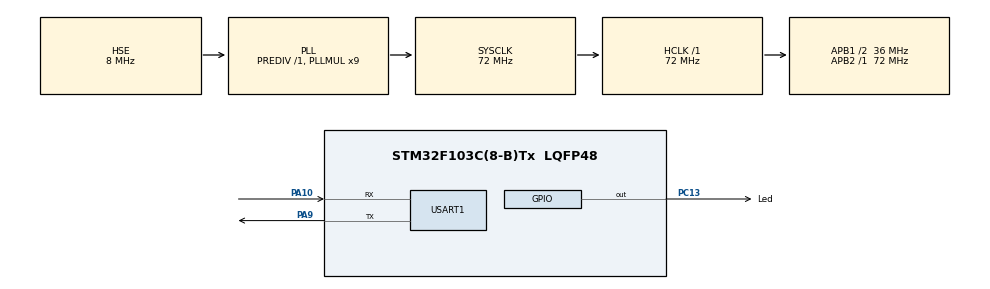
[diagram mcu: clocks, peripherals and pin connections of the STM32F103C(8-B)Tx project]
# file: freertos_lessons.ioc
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FREERTOS.INCLUDE_vTaskDelayUntil=1
FREERTOS.Tasks01=defaultTask,0,128,StartDefaultTask,Default,NULL,Dynamic,NULL,NULL
FREERTOS.configTICK_RATE_HZ=100
FREERTOS.configUSE_IDLE_HOOK=1
FREERTOS.configUSE_PREEMPTION=0
Mcu.Family=STM32F1
Mcu.Name=STM32F103C(8-B)Tx
Mcu.Package=LQFP48
NVIC.PriorityGroup=NVIC_PRIORITYGROUP_4
NVIC.TIM1_UP_IRQn=true\:0\:0\:false\:false\:true\:false\:false\:true
NVIC.TimeBase=TIM1_UP_IRQn
NVIC.TimeBaseIP=TIM1
PA10.Mode=Asynchronous
PA10.Signal=USART1_RX
PA13.Mode=Serial_Wire
PA13.Signal=SYS_JTMS-SWDIO
PA14.Mode=Serial_Wire
PA14.Signal=SYS_JTCK-SWCLK
PA9.Mode=Asynchronous
PA9.Signal=USART1_TX
PC13-TAMPER-RTC.GPIO_Label=Led
PC13-TAMPER-RTC.Signal=GPIO_Output
PD0-OSC_IN.Mode=HSE-External-Oscillator
PD0-OSC_IN.Signal=RCC_OSC_IN
PD1-OSC_OUT.Mode=HSE-External-Oscillator
PD1-OSC_OUT.Signal=RCC_OSC_OUT
ProjectManager.HeapSize=0x200
ProjectManager.StackSize=0x400
ProjectManager.TargetToolchain=STM32CubeIDE
RCC.AHBFreq_Value=72000000
RCC.APB1CLKDivider=RCC_HCLK_DIV2
RCC.APB1Freq_Value=36000000
RCC.APB1TimFreq_Value=72000000
RCC.APB2Freq_Value=72000000
RCC.APB2TimFreq_Value=72000000
RCC.HCLKFreq_Value=72000000
RCC.PLLMUL=RCC_PLL_MUL9
RCC.PLLSourceVirtual=RCC_PLLSOURCE_HSE
RCC.SYSCLKFreq_VALUE=72000000
RCC.SYSCLKSource=RCC_SYSCLKSOURCE_PLLCLK
RCC.USBFreq_Value=72000000
USART1.VirtualMode=VM_ASYNC
VP_FREERTOS_VS_CMSIS_V1.Mode=CMSIS_V1
VP_SYS_VS_tim1.Mode=TIM1
board=custom

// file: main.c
/* USER CODE BEGIN Header */
/**
  ******************************************************************************
  * @file           : main.c
  * @brief          : Main program body
  ******************************************************************************
  * @attention
  *
  * <h2><center>&copy; Copyright (c) 2021 STMicroelectronics.
  * All rights reserved.</center></h2>
  *
  * This software component is licensed by ST under BSD 3-Clause license,
  * the "License"; You may not use this file except in compliance with the
  * License. You may obtain a copy of the License at:
  *                        opensource.org/licenses/BSD-3-Clause
  *
  ******************************************************************************
  */
/* USER CODE END Header */
#include "main.h"
#include "cmsis_os.h"

/* USER CODE BEGIN PD */
#define MY_STR "State of led pin is:  \r\n"
/* USER CODE END PD */

UART_HandleTypeDef huart1;

osThreadId defaultTaskHandle;
/* USER CODE BEGIN PV */
uint8_t input_value = 0;
/* USER CODE END PV */

void SystemClock_Config(void);
static void MX_GPIO_Init(void);
static void MX_USART1_UART_Init(void);
void StartDefaultTask(void const * argument);

/* USER CODE BEGIN PFP */
void BlinkingLedUntilTask();
void input_handler_task();
void config_output_task();
void led_status_task();
/* USER CODE END PFP */

int main(void)
{

  /* MCU Configuration--------------------------------------------------------*/

  /* Reset of all peripherals, Initializes the Flash interface and the Systick. */
  HAL_Init();

  /* Configure the system clock */
  SystemClock_Config();

  /* Initialize all configured peripherals */
  MX_GPIO_Init();
  MX_USART1_UART_Init();

  /* USER CODE BEGIN RTOS_QUEUES */
  /* add queues, ... */
  if (0) {
  /* USER CODE END RTOS_QUEUES */

  /* Create the thread(s) */
  /* definition and creation of defaultTask */
  osThreadDef(defaultTask, StartDefaultTask, osPriorityNormal, 0, 128);
  defaultTaskHandle = osThreadCreate(osThread(defaultTask), NULL);

  /* USER CODE BEGIN RTOS_THREADS */
  }
//  xTaskCreate(BlinkingLedUntilTask, NULL, configMINIMAL_STACK_SIZE, NULL, 1, NULL);
  xTaskCreate(input_handler_task, NULL, configMINIMAL_STACK_SIZE, NULL, 1, NULL);
  xTaskCreate(config_output_task, NULL, configMINIMAL_STACK_SIZE, NULL, 2, NULL);
  xTaskCreate(led_status_task, NULL, configMINIMAL_STACK_SIZE, NULL, 3, NULL);
  vTaskStartScheduler();
  /* add threads, ... */
  /* USER CODE END RTOS_THREADS */

  /* Start scheduler */
  osKernelStart();

  /* We should never get here as control is now taken by the scheduler */
  /* Infinite loop */
  /* USER CODE BEGIN WHILE */
//  osKernelStop();

  while (1)
  {
    /* USER CODE END WHILE */

  }
}

void SystemClock_Config(void)
{
  RCC_OscInitTypeDef RCC_OscInitStruct = {0};
  RCC_ClkInitTypeDef RCC_ClkInitStruct = {0};

  /** Initializes the RCC Oscillators according to the specified parameters
  * in the RCC_OscInitTypeDef structure.
  */
  RCC_OscInitStruct.OscillatorType = RCC_OSCILLATORTYPE_HSE;
  RCC_OscInitStruct.HSEState = RCC_HSE_ON;
  RCC_OscInitStruct.HSEPredivValue = RCC_HSE_PREDIV_DIV1;
  RCC_OscInitStruct.HSIState = RCC_HSI_ON;
  RCC_OscInitStruct.PLL.PLLState = RCC_PLL_ON;
  RCC_OscInitStruct.PLL.PLLSource = RCC_PLLSOURCE_HSE;
  RCC_OscInitStruct.PLL.PLLMUL = RCC_PLL_MUL9;
  if (HAL_RCC_OscConfig(&RCC_OscInitStruct) != HAL_OK)
  {
    Error_Handler();
  }
  /** Initializes the CPU, AHB and APB buses clocks
  */
  RCC_ClkInitStruct.ClockType = RCC_CLOCKTYPE_HCLK|RCC_CLOCKTYPE_SYSCLK
                              |RCC_CLOCKTYPE_PCLK1|RCC_CLOCKTYPE_PCLK2;
  RCC_ClkInitStruct.SYSCLKSource = RCC_SYSCLKSOURCE_PLLCLK;
  RCC_ClkInitStruct.AHBCLKDivider = RCC_SYSCLK_DIV1;
  RCC_ClkInitStruct.APB1CLKDivider = RCC_HCLK_DIV2;
  RCC_ClkInitStruct.APB2CLKDivider = RCC_HCLK_DIV1;

  if (HAL_RCC_ClockConfig(&RCC_ClkInitStruct, FLASH_LATENCY_2) != HAL_OK)
  {
    Error_Handler();
  }
}

static void MX_USART1_UART_Init(void)
{

  huart1.Instance = USART1;
  huart1.Init.BaudRate = 9600;
  huart1.Init.WordLength = UART_WORDLENGTH_9B;
  huart1.Init.StopBits = UART_STOPBITS_1;
  huart1.Init.Parity = UART_PARITY_EVEN;
  huart1.Init.Mode = UART_MODE_TX_RX;
  huart1.Init.HwFlowCtl = UART_HWCONTROL_NONE;
  huart1.Init.OverSampling = UART_OVERSAMPLING_16;
  if (HAL_UART_Init(&huart1) != HAL_OK)
  {
    Error_Handler();
  }

}

static void MX_GPIO_Init(void)
{
  GPIO_InitTypeDef GPIO_InitStruct = {0};

  /* GPIO Ports Clock Enable */
  __HAL_RCC_GPIOC_CLK_ENABLE();
  __HAL_RCC_GPIOD_CLK_ENABLE();
  __HAL_RCC_GPIOA_CLK_ENABLE();

  /*Configure GPIO pin Output Level */
  HAL_GPIO_WritePin(Led_GPIO_Port, Led_Pin, GPIO_PIN_RESET);

  /*Configure GPIO pin : Led_Pin */
  GPIO_InitStruct.Pin = Led_Pin;
  GPIO_InitStruct.Mode = GPIO_MODE_OUTPUT_PP;
  GPIO_InitStruct.Pull = GPIO_NOPULL;
  GPIO_InitStruct.Speed = GPIO_SPEED_FREQ_LOW;
  HAL_GPIO_Init(Led_GPIO_Port, &GPIO_InitStruct);

}

/* USER CODE BEGIN 4 */

void BlinkingLedTask()
{
	//инициализация
	for(;;){ // тело задачи
		HAL_GPIO_TogglePin(Led_GPIO_Port, Led_Pin);
		vTaskDelay(50);
	}
	vTaskDelete(NULL);
}

void BlinkingLedUntilTask()
{
	//инициализация
	TickType_t olSysTime;
	const TickType_t period = 20;
	olSysTime = xTaskGetTickCount();
	char str[sizeof(MY_STR)] = MY_STR;

	for(;;){ // тело задачи
		HAL_GPIO_TogglePin(Led_GPIO_Port, Led_Pin);
		if (HAL_GPIO_ReadPin(Led_GPIO_Port, Led_Pin)) {
			str[21] = '1';
//			status_led = 1;
		} else {
			str[21] = '0';
		}

		HAL_UART_Transmit(&huart1, (uint8_t *)str, sizeof(MY_STR), 100);
		vTaskDelayUntil(&olSysTime, period);
	}
	vTaskDelete(NULL);
}

void vAplicationIdleHook(){
	static uint32_t x = 0;
	x++;
}

//в каких состояниях может находится эта задача?
void input_handler_task()
{
	//инициализация
	for (;;){
		HAL_UART_Receive(&huart1, &input_value, 1, 1);
	}
	vTaskDelete(NULL);
}

//в каких состояниях может находится эта задача?
void config_output_task()
{
	//инициализация
	for (;;){
		if (input_value) {
			HAL_GPIO_WritePin(Led_GPIO_Port, Led_Pin, GPIO_PIN_RESET);
		} else {
			HAL_GPIO_WritePin(Led_GPIO_Port, Led_Pin, GPIO_PIN_SET);
		}
	}
	vTaskDelete(NULL);
}

//в каких состояниях может находится эта задача?
void led_status_task()
{
	//инициализация
	TickType_t olSysTime;
	const TickType_t period = 10;
	olSysTime = xTaskGetTickCount();
	char str[sizeof(MY_STR)] = MY_STR;

	for(;;){ // тело задачи
		if (HAL_GPIO_ReadPin(Led_GPIO_Port, Led_Pin)) {
			str[21] = '1';
		} else {
			str[21] = '0';
		}

		HAL_UART_Transmit(&huart1, (uint8_t *)str, sizeof(MY_STR), 100);
		vTaskDelayUntil(&olSysTime, period);
	}
	vTaskDelete(NULL);
}

void template_task()
{
	//инициализация
	for (;;){ //поток

	}
	vTaskDelete(NULL);
}

//Вопрос: в каких состояниях могут находиться задачи led_status_task, config_output_task, input_handler_task
//после запуска планировщика, если приоритеты равны:
//а) led_status_task = 1, config_output_task = 2, input_handler_task = 3
//б) led_status_task = 3, config_output_task = 1, input_handler_task = 2
//в) led_status_task = 2, config_output_task = 3, input_handler_task = 1?
/* USER CODE END 4 */

void StartDefaultTask(void const * argument)
{
  /* USER CODE BEGIN 5 */
  /* Infinite loop */
  for(;;)
  {
    osDelay(500);
    HAL_GPIO_TogglePin(GPIOC, GPIO_PIN_13);
  }
  /* USER CODE END 5 */
}

 /**
  * @brief  Period elapsed callback in non blocking mode
  * @note   This function is called  when TIM1 interrupt took place, inside
  * HAL_TIM_IRQHandler(). It makes a direct call to HAL_IncTick() to increment
  * a global variable "uwTick" used as application time base.
  * @param  htim : TIM handle
  * @retval None
  */
void HAL_TIM_PeriodElapsedCallback(TIM_HandleTypeDef *htim)
{
  if (htim->Instance == TIM1) {
    HAL_IncTick();
  }
}

void Error_Handler(void)
{
  __disable_irq();
  while (1)
  {
  }
}

/************************ (C) COPYRIGHT STMicroelectronics *****END OF FILE****/
